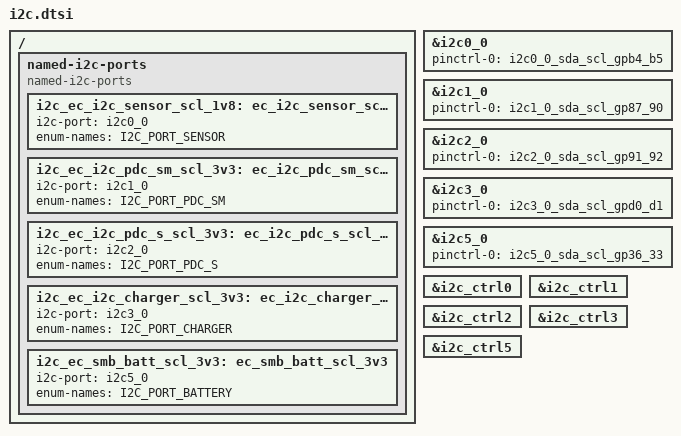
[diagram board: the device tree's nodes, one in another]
/* Copyright 2025 The ChromiumOS Authors
 * Use of this source code is governed by a BSD-style license that can be
 * found in the LICENSE file.
 */

#include <dt-bindings/usb_pd_tcpm.h>

/ {
	named-i2c-ports {
		compatible = "named-i2c-ports";

		i2c_ec_i2c_sensor_scl_1v8: ec_i2c_sensor_scl_1v8 {
			i2c-port = <&i2c0_0>;
			enum-names = "I2C_PORT_SENSOR";
		};
		i2c_ec_i2c_pdc_sm_scl_3v3: ec_i2c_pdc_sm_scl_3v3 {
			i2c-port = <&i2c1_0>;
			enum-names = "I2C_PORT_PDC_SM";
		};
		i2c_ec_i2c_pdc_s_scl_3v3: ec_i2c_pdc_s_scl_3v3 {
			i2c-port = <&i2c2_0>;
			enum-names = "I2C_PORT_PDC_S";
		};
		i2c_ec_i2c_charger_scl_3v3: ec_i2c_charger_scl_3v3 {
			i2c-port = <&i2c3_0>;
			enum-names = "I2C_PORT_CHARGER";
		};
		i2c_ec_smb_batt_scl_3v3: ec_smb_batt_scl_3v3 {
			i2c-port = <&i2c5_0>;
			enum-names = "I2C_PORT_BATTERY";
		};
	};
};

&i2c0_0 {
	status = "okay";
	pinctrl-0 = <&i2c0_0_sda_scl_gpb4_b5>;
	pinctrl-names = "default";
};

&i2c1_0 {
	status = "okay";
	pinctrl-0 = <&i2c1_0_sda_scl_gp87_90>;
	pinctrl-names = "default";
};

&i2c2_0 {
	status = "okay";
	pinctrl-0 = <&i2c2_0_sda_scl_gp91_92>;
	pinctrl-names = "default";
};

&i2c3_0 {
	status = "okay";
	pinctrl-0 = <&i2c3_0_sda_scl_gpd0_d1>;
	pinctrl-names = "default";
};

&i2c5_0 {
	status = "okay";
	pinctrl-0 = <&i2c5_0_sda_scl_gp36_33>;
	pinctrl-names = "default";
};

&i2c_ctrl0 {
	status = "okay";
};

&i2c_ctrl1 {
	status = "okay";
};

&i2c_ctrl2 {
	status = "okay";
};

&i2c_ctrl3 {
	status = "okay";
};

&i2c_ctrl5 {
	status = "okay";
};
